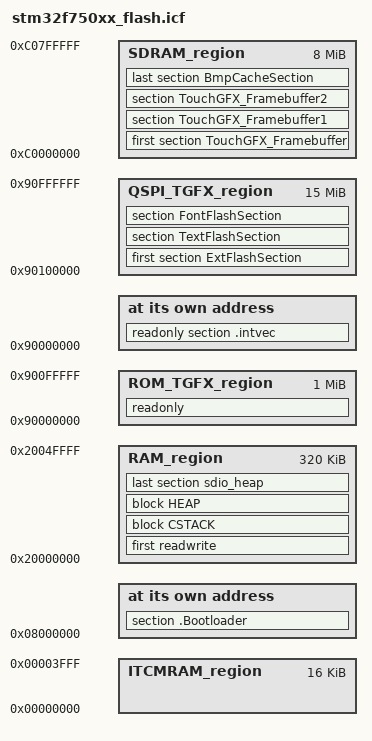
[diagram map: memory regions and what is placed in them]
/*###ICF### Section handled by ICF editor, don't touch! ****/
/*-Editor annotation file-*/
/* IcfEditorFile="$TOOLKIT_DIR$\config\ide\IcfEditor\cortex_v1_0.xml" */
/*-Specials-*/
define symbol __ICFEDIT_intvec_start__ = 0x90000000;
/*-Memory Regions-*/
define symbol __ICFEDIT_region_ROM_TGFX_start__   = 0x90000000;
define symbol __ICFEDIT_region_ROM_TGFX_end__     = 0x900FFFFF; /* 1024 Kbytes for TouchGFX demo */

/*-Internal RAM Memory Regions-*/
define symbol __ICFEDIT_region_RAM_start__        = 0x20000000;
define symbol __ICFEDIT_region_RAM_end__          = 0x2004FFFF;
define symbol __ICFEDIT_region_ITCMRAM_start__    = 0x00000000;
define symbol __ICFEDIT_region_ITCMRAM_end__      = 0x00003FFF;

/*-External RAM Memory Regions-*/
define symbol __ICFEDIT_region_SDRAM_start__      = 0xC0000000; /*   8 Mbytes */
define symbol __ICFEDIT_region_SDRAM_end__        = 0xC07FFFFF;

/*-Quad-SPI Memory Regions-*/
define symbol __ICFEDIT_region_QSPI_TGFX_start__  = 0x90100000;
define symbol __ICFEDIT_region_QSPI_TGFX_end__    = 0x90FFFFFF; /* 15 Mbytes for TouchGFX demo */

/*-Sizes-*/
define symbol __ICFEDIT_size_cstack__ = 0x1000;
define symbol __ICFEDIT_size_heap__   = 0x1000;
/**** End of ICF editor section. ###ICF###*/

define memory mem with size = 4G;
define region ROM_TGFX_region   = mem:[from __ICFEDIT_region_ROM_TGFX_start__   to __ICFEDIT_region_ROM_TGFX_end__];
define region ITCMRAM_region    = mem:[from __ICFEDIT_region_ITCMRAM_start__    to __ICFEDIT_region_ITCMRAM_end__];
define region RAM_region        = mem:[from __ICFEDIT_region_RAM_start__        to __ICFEDIT_region_RAM_end__];
define region SDRAM_region      = mem:[from __ICFEDIT_region_SDRAM_start__      to __ICFEDIT_region_SDRAM_end__];
define region QSPI_TGFX_region  = mem:[from __ICFEDIT_region_QSPI_TGFX_start__  to __ICFEDIT_region_QSPI_TGFX_end__];

define block CSTACK     with alignment = 8, size = __ICFEDIT_size_cstack__    { };
define block HEAP       with alignment = 8, size = __ICFEDIT_size_heap__      { };

initialize by copy { readwrite };
do not initialize  { section .noinit, section TouchGFX_Framebuffer, section TouchGFX_Framebuffer1, section TouchGFX_Framebuffer2, section BmpCacheSection };

place at address mem:__ICFEDIT_intvec_start__ { readonly section .intvec };
place at address mem:0x08000000 { section .Bootloader };

place in ITCMRAM_region     { };
place in RAM_region         { first readwrite, block CSTACK, block HEAP, last section sdio_heap };
place in SDRAM_region       { first section TouchGFX_Framebuffer, section TouchGFX_Framebuffer1, section TouchGFX_Framebuffer2, last section BmpCacheSection };
place in ROM_TGFX_region    { readonly };
place in QSPI_TGFX_region   { first section ExtFlashSection
                            , section TextFlashSection
                            , section FontFlashSection };
